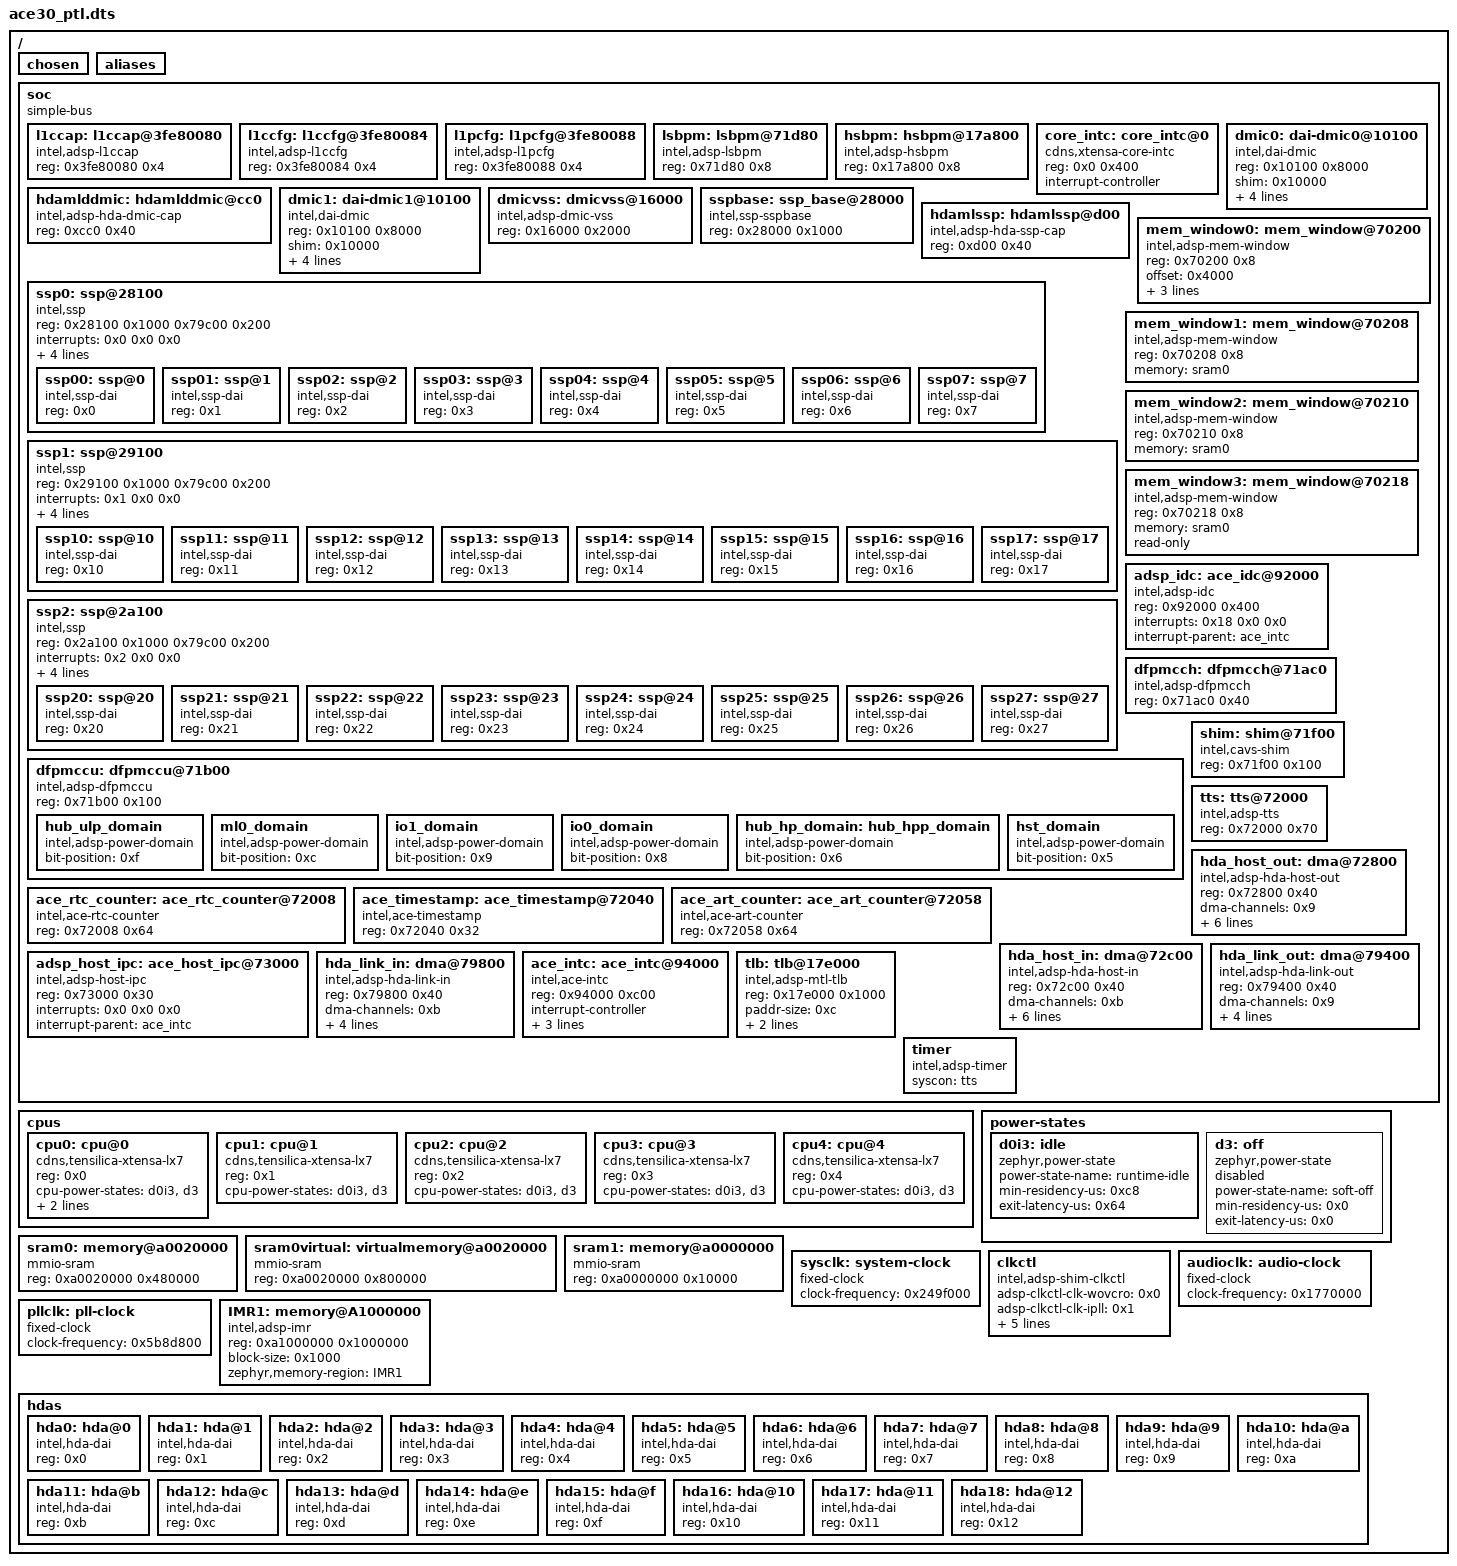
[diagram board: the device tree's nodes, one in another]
/dts-v1/;

/ {
	#address-cells = < 0x1 >;
	#size-cells = < 0x1 >;
	chosen {
	};
	aliases {
	};
	soc {
		#address-cells = < 0x1 >;
		#size-cells = < 0x1 >;
		compatible = "simple-bus";
		ranges;
		l1ccap: l1ccap@3fe80080 {
			compatible = "intel,adsp-l1ccap";
			reg = < 0x3fe80080 0x4 >;
		};
		l1ccfg: l1ccfg@3fe80084 {
			compatible = "intel,adsp-l1ccfg";
			reg = < 0x3fe80084 0x4 >;
		};
		l1pcfg: l1pcfg@3fe80088 {
			compatible = "intel,adsp-l1pcfg";
			reg = < 0x3fe80088 0x4 >;
		};
		lsbpm: lsbpm@71d80 {
			compatible = "intel,adsp-lsbpm";
			reg = < 0x71d80 0x8 >;
		};
		hsbpm: hsbpm@17a800 {
			compatible = "intel,adsp-hsbpm";
			reg = < 0x17a800 0x8 >;
		};
		core_intc: core_intc@0 {
			compatible = "cdns,xtensa-core-intc";
			reg = < 0x0 0x400 >;
			interrupt-controller;
			#interrupt-cells = < 0x3 >;
			phandle = < 0x8 >;
		};
		hdamlddmic: hdamlddmic@cc0 {
			compatible = "intel,adsp-hda-dmic-cap";
			reg = < 0xcc0 0x40 >;
			status = "okay";
		};
		dmic0: dai-dmic0@10100 {
			compatible = "intel,dai-dmic";
			reg = < 0x10100 0x8000 >;
			shim = < 0x10000 >;
			fifo = < 0x8 >;
			interrupts = < 0x8 0x0 0x0 >;
			interrupt-parent = < &ace_intc >;
			power-domain = < &hub_ulp_domain >;
		};
		dmic1: dai-dmic1@10100 {
			compatible = "intel,dai-dmic";
			reg = < 0x10100 0x8000 >;
			shim = < 0x10000 >;
			fifo = < 0x108 >;
			interrupts = < 0x8 0x0 0x0 >;
			interrupt-parent = < &ace_intc >;
			power-domain = < &hub_ulp_domain >;
		};
		dmicvss: dmicvss@16000 {
			compatible = "intel,adsp-dmic-vss";
			reg = < 0x16000 0x2000 >;
			status = "okay";
		};
		sspbase: ssp_base@28000 {
			compatible = "intel,ssp-sspbase";
			reg = < 0x28000 0x1000 >;
		};
		hdamlssp: hdamlssp@d00 {
			compatible = "intel,adsp-hda-ssp-cap";
			reg = < 0xd00 0x40 >;
			status = "okay";
		};
		ssp0: ssp@28100 {
			compatible = "intel,ssp";
			#address-cells = < 0x1 >;
			#size-cells = < 0x0 >;
			reg = < 0x28100 0x1000 0x79c00 0x200 >;
			interrupts = < 0x0 0x0 0x0 >;
			interrupt-parent = < &ace_intc >;
			dmas = < &hda_link_out 0x1 &hda_link_in 0x1 >;
			dma-names = "tx", "rx";
			ssp-index = < 0x0 >;
			power-domain = < &io0_domain >;
			status = "okay";
			ssp00: ssp@0 {
				compatible = "intel,ssp-dai";
				reg = < 0x0 >;
				status = "okay";
			};
			ssp01: ssp@1 {
				compatible = "intel,ssp-dai";
				reg = < 0x1 >;
				status = "okay";
			};
			ssp02: ssp@2 {
				compatible = "intel,ssp-dai";
				reg = < 0x2 >;
				status = "okay";
			};
			ssp03: ssp@3 {
				compatible = "intel,ssp-dai";
				reg = < 0x3 >;
				status = "okay";
			};
			ssp04: ssp@4 {
				compatible = "intel,ssp-dai";
				reg = < 0x4 >;
				status = "okay";
			};
			ssp05: ssp@5 {
				compatible = "intel,ssp-dai";
				reg = < 0x5 >;
				status = "okay";
			};
			ssp06: ssp@6 {
				compatible = "intel,ssp-dai";
				reg = < 0x6 >;
				status = "okay";
			};
			ssp07: ssp@7 {
				compatible = "intel,ssp-dai";
				reg = < 0x7 >;
				status = "okay";
			};
		};
		ssp1: ssp@29100 {
			compatible = "intel,ssp";
			#address-cells = < 0x1 >;
			#size-cells = < 0x0 >;
			reg = < 0x29100 0x1000 0x79c00 0x200 >;
			interrupts = < 0x1 0x0 0x0 >;
			interrupt-parent = < &ace_intc >;
			dmas = < &hda_link_out 0x2 &hda_link_in 0x2 >;
			dma-names = "tx", "rx";
			ssp-index = < 0x1 >;
			power-domain = < &io0_domain >;
			status = "okay";
			ssp10: ssp@10 {
				compatible = "intel,ssp-dai";
				reg = < 0x10 >;
				status = "okay";
			};
			ssp11: ssp@11 {
				compatible = "intel,ssp-dai";
				reg = < 0x11 >;
				status = "okay";
			};
			ssp12: ssp@12 {
				compatible = "intel,ssp-dai";
				reg = < 0x12 >;
				status = "okay";
			};
			ssp13: ssp@13 {
				compatible = "intel,ssp-dai";
				reg = < 0x13 >;
				status = "okay";
			};
			ssp14: ssp@14 {
				compatible = "intel,ssp-dai";
				reg = < 0x14 >;
				status = "okay";
			};
			ssp15: ssp@15 {
				compatible = "intel,ssp-dai";
				reg = < 0x15 >;
				status = "okay";
			};
			ssp16: ssp@16 {
				compatible = "intel,ssp-dai";
				reg = < 0x16 >;
				status = "okay";
			};
			ssp17: ssp@17 {
				compatible = "intel,ssp-dai";
				reg = < 0x17 >;
				status = "okay";
			};
		};
		ssp2: ssp@2a100 {
			compatible = "intel,ssp";
			#address-cells = < 0x1 >;
			#size-cells = < 0x0 >;
			reg = < 0x2a100 0x1000 0x79c00 0x200 >;
			interrupts = < 0x2 0x0 0x0 >;
			interrupt-parent = < &ace_intc >;
			dmas = < &hda_link_out 0x3 &hda_link_in 0x3 >;
			dma-names = "tx", "rx";
			ssp-index = < 0x2 >;
			power-domain = < &io0_domain >;
			status = "okay";
			ssp20: ssp@20 {
				compatible = "intel,ssp-dai";
				reg = < 0x20 >;
				status = "okay";
			};
			ssp21: ssp@21 {
				compatible = "intel,ssp-dai";
				reg = < 0x21 >;
				status = "okay";
			};
			ssp22: ssp@22 {
				compatible = "intel,ssp-dai";
				reg = < 0x22 >;
				status = "okay";
			};
			ssp23: ssp@23 {
				compatible = "intel,ssp-dai";
				reg = < 0x23 >;
				status = "okay";
			};
			ssp24: ssp@24 {
				compatible = "intel,ssp-dai";
				reg = < 0x24 >;
				status = "okay";
			};
			ssp25: ssp@25 {
				compatible = "intel,ssp-dai";
				reg = < 0x25 >;
				status = "okay";
			};
			ssp26: ssp@26 {
				compatible = "intel,ssp-dai";
				reg = < 0x26 >;
				status = "okay";
			};
			ssp27: ssp@27 {
				compatible = "intel,ssp-dai";
				reg = < 0x27 >;
				status = "okay";
			};
		};
		mem_window0: mem_window@70200 {
			compatible = "intel,adsp-mem-window";
			reg = < 0x70200 0x8 >;
			offset = < 0x4000 >;
			memory = < &sram0 >;
			initialize;
			read-only;
		};
		mem_window1: mem_window@70208 {
			compatible = "intel,adsp-mem-window";
			reg = < 0x70208 0x8 >;
			memory = < &sram0 >;
		};
		mem_window2: mem_window@70210 {
			compatible = "intel,adsp-mem-window";
			reg = < 0x70210 0x8 >;
			memory = < &sram0 >;
		};
		mem_window3: mem_window@70218 {
			compatible = "intel,adsp-mem-window";
			reg = < 0x70218 0x8 >;
			memory = < &sram0 >;
			read-only;
		};
		adsp_idc: ace_idc@92000 {
			compatible = "intel,adsp-idc";
			reg = < 0x92000 0x400 >;
			interrupts = < 0x18 0x0 0x0 >;
			interrupt-parent = < &ace_intc >;
		};
		dfpmcch: dfpmcch@71ac0 {
			compatible = "intel,adsp-dfpmcch";
			reg = < 0x71ac0 0x40 >;
		};
		dfpmccu: dfpmccu@71b00 {
			compatible = "intel,adsp-dfpmccu";
			reg = < 0x71b00 0x100 >;
			hub_ulp_domain: hub_ulp_domain {
				compatible = "intel,adsp-power-domain";
				bit-position = < 0xf >;
				phandle = < 0x2 >;
			};
			ml0_domain: ml0_domain {
				compatible = "intel,adsp-power-domain";
				bit-position = < 0xc >;
			};
			io1_domain: io1_domain {
				compatible = "intel,adsp-power-domain";
				bit-position = < 0x9 >;
			};
			io0_domain: io0_domain {
				compatible = "intel,adsp-power-domain";
				bit-position = < 0x8 >;
				phandle = < 0x5 >;
			};
			hub_hp_domain: hub_hpp_domain {
				compatible = "intel,adsp-power-domain";
				bit-position = < 0x6 >;
			};
			hst_domain: hst_domain {
				compatible = "intel,adsp-power-domain";
				bit-position = < 0x5 >;
				phandle = < 0x7 >;
			};
		};
		shim: shim@71f00 {
			compatible = "intel,cavs-shim";
			reg = < 0x71f00 0x100 >;
		};
		tts: tts@72000 {
			compatible = "intel,adsp-tts";
			reg = < 0x72000 0x70 >;
			status = "okay";
			phandle = < 0x9 >;
		};
		ace_rtc_counter: ace_rtc_counter@72008 {
			compatible = "intel,ace-rtc-counter";
			reg = < 0x72008 0x64 >;
		};
		ace_timestamp: ace_timestamp@72040 {
			compatible = "intel,ace-timestamp";
			reg = < 0x72040 0x32 >;
		};
		ace_art_counter: ace_art_counter@72058 {
			compatible = "intel,ace-art-counter";
			reg = < 0x72058 0x64 >;
		};
		hda_host_out: dma@72800 {
			compatible = "intel,adsp-hda-host-out";
			#dma-cells = < 0x1 >;
			reg = < 0x72800 0x40 >;
			dma-channels = < 0x9 >;
			dma-buf-addr-alignment = < 0x80 >;
			dma-buf-size-alignment = < 0x20 >;
			dma-copy-alignment = < 0x20 >;
			power-domain = < &hst_domain >;
			interrupts = < 0xd 0x0 0x0 >;
			interrupt-parent = < &ace_intc >;
			status = "okay";
		};
		hda_host_in: dma@72c00 {
			compatible = "intel,adsp-hda-host-in";
			#dma-cells = < 0x1 >;
			reg = < 0x72c00 0x40 >;
			dma-channels = < 0xb >;
			dma-buf-addr-alignment = < 0x80 >;
			dma-buf-size-alignment = < 0x20 >;
			dma-copy-alignment = < 0x20 >;
			power-domain = < &hst_domain >;
			interrupts = < 0xc 0x0 0x0 >;
			interrupt-parent = < &ace_intc >;
			status = "okay";
		};
		adsp_host_ipc: ace_host_ipc@73000 {
			compatible = "intel,adsp-host-ipc";
			status = "okay";
			reg = < 0x73000 0x30 >;
			interrupts = < 0x0 0x0 0x0 >;
			interrupt-parent = < &ace_intc >;
		};
		hda_link_out: dma@79400 {
			compatible = "intel,adsp-hda-link-out";
			#dma-cells = < 0x1 >;
			reg = < 0x79400 0x40 >;
			dma-channels = < 0x9 >;
			dma-buf-addr-alignment = < 0x80 >;
			dma-buf-size-alignment = < 0x20 >;
			dma-copy-alignment = < 0x20 >;
			power-domain = < &io0_domain >;
			status = "okay";
			phandle = < 0x3 >;
		};
		hda_link_in: dma@79800 {
			compatible = "intel,adsp-hda-link-in";
			#dma-cells = < 0x1 >;
			reg = < 0x79800 0x40 >;
			dma-channels = < 0xb >;
			dma-buf-addr-alignment = < 0x80 >;
			dma-buf-size-alignment = < 0x20 >;
			dma-copy-alignment = < 0x20 >;
			power-domain = < &io0_domain >;
			status = "okay";
			phandle = < 0x4 >;
		};
		ace_intc: ace_intc@94000 {
			compatible = "intel,ace-intc";
			reg = < 0x94000 0xc00 >;
			interrupt-controller;
			#interrupt-cells = < 0x3 >;
			interrupts = < 0x4 0x0 0x0 >;
			num-irqs = < 0x1c >;
			interrupt-parent = < &core_intc >;
			phandle = < 0x1 >;
		};
		tlb: tlb@17e000 {
			compatible = "intel,adsp-mtl-tlb";
			reg = < 0x17e000 0x1000 >;
			paddr-size = < 0xc >;
			exec-bit-idx = < 0xe >;
			write-bit-idx = < 0xf >;
		};
		timer: timer {
			compatible = "intel,adsp-timer";
			syscon = < &tts >;
		};
	};
	cpus {
		#address-cells = < 0x1 >;
		#size-cells = < 0x0 >;
		cpu0: cpu@0 {
			device_type = "cpu";
			compatible = "cdns,tensilica-xtensa-lx7";
			reg = < 0x0 >;
			cpu-power-states = < &d0i3 &d3 >;
			i-cache-line-size = < 0x40 >;
			d-cache-line-size = < 0x40 >;
		};
		cpu1: cpu@1 {
			device_type = "cpu";
			compatible = "cdns,tensilica-xtensa-lx7";
			reg = < 0x1 >;
			cpu-power-states = < &d0i3 &d3 >;
		};
		cpu2: cpu@2 {
			device_type = "cpu";
			compatible = "cdns,tensilica-xtensa-lx7";
			reg = < 0x2 >;
			cpu-power-states = < &d0i3 &d3 >;
		};
		cpu3: cpu@3 {
			device_type = "cpu";
			compatible = "cdns,tensilica-xtensa-lx7";
			reg = < 0x3 >;
			cpu-power-states = < &d0i3 &d3 >;
		};
		cpu4: cpu@4 {
			device_type = "cpu";
			compatible = "cdns,tensilica-xtensa-lx7";
			reg = < 0x4 >;
			cpu-power-states = < &d0i3 &d3 >;
		};
	};
	power-states {
		d0i3: idle {
			compatible = "zephyr,power-state";
			power-state-name = "runtime-idle";
			min-residency-us = < 0xc8 >;
			exit-latency-us = < 0x64 >;
			phandle = < 0xa >;
		};
		d3: off {
			compatible = "zephyr,power-state";
			power-state-name = "soft-off";
			min-residency-us = < 0x0 >;
			exit-latency-us = < 0x0 >;
			status = "disabled";
			phandle = < 0xb >;
		};
	};
	sram0: memory@a0020000 {
		device_type = "memory";
		compatible = "mmio-sram";
		reg = < 0xa0020000 0x480000 >;
		phandle = < 0x6 >;
	};
	sram0virtual: virtualmemory@a0020000 {
		device_type = "memory";
		compatible = "mmio-sram";
		reg = < 0xa0020000 0x800000 >;
	};
	sram1: memory@a0000000 {
		device_type = "memory";
		compatible = "mmio-sram";
		reg = < 0xa0000000 0x10000 >;
	};
	sysclk: system-clock {
		compatible = "fixed-clock";
		clock-frequency = < 0x249f000 >;
		#clock-cells = < 0x0 >;
	};
	clkctl: clkctl {
		compatible = "intel,adsp-shim-clkctl";
		adsp-clkctl-clk-wovcro = < 0x0 >;
		adsp-clkctl-clk-ipll = < 0x1 >;
		adsp-clkctl-freq-enc = < 0xc 0x4 >;
		adsp-clkctl-freq-mask = < 0x0 0x0 >;
		adsp-clkctl-freq-default = < 0x1 >;
		adsp-clkctl-freq-lowest = < 0x0 >;
		wovcro-supported;
	};
	audioclk: audio-clock {
		compatible = "fixed-clock";
		clock-frequency = < 0x1770000 >;
		#clock-cells = < 0x0 >;
	};
	pllclk: pll-clock {
		compatible = "fixed-clock";
		clock-frequency = < 0x5b8d800 >;
		#clock-cells = < 0x0 >;
	};
	IMR1: memory@A1000000 {
		compatible = "intel,adsp-imr";
		reg = < 0xa1000000 0x1000000 >;
		block-size = < 0x1000 >;
		zephyr,memory-region = "IMR1";
	};
	hdas {
		#address-cells = < 0x1 >;
		#size-cells = < 0x0 >;
		hda0: hda@0 {
			compatible = "intel,hda-dai";
			status = "okay";
			reg = < 0x0 >;
		};
		hda1: hda@1 {
			compatible = "intel,hda-dai";
			status = "okay";
			reg = < 0x1 >;
		};
		hda2: hda@2 {
			compatible = "intel,hda-dai";
			status = "okay";
			reg = < 0x2 >;
		};
		hda3: hda@3 {
			compatible = "intel,hda-dai";
			status = "okay";
			reg = < 0x3 >;
		};
		hda4: hda@4 {
			compatible = "intel,hda-dai";
			status = "okay";
			reg = < 0x4 >;
		};
		hda5: hda@5 {
			compatible = "intel,hda-dai";
			status = "okay";
			reg = < 0x5 >;
		};
		hda6: hda@6 {
			compatible = "intel,hda-dai";
			status = "okay";
			reg = < 0x6 >;
		};
		hda7: hda@7 {
			compatible = "intel,hda-dai";
			status = "okay";
			reg = < 0x7 >;
		};
		hda8: hda@8 {
			compatible = "intel,hda-dai";
			status = "okay";
			reg = < 0x8 >;
		};
		hda9: hda@9 {
			compatible = "intel,hda-dai";
			status = "okay";
			reg = < 0x9 >;
		};
		hda10: hda@a {
			compatible = "intel,hda-dai";
			status = "okay";
			reg = < 0xa >;
		};
		hda11: hda@b {
			compatible = "intel,hda-dai";
			status = "okay";
			reg = < 0xb >;
		};
		hda12: hda@c {
			compatible = "intel,hda-dai";
			status = "okay";
			reg = < 0xc >;
		};
		hda13: hda@d {
			compatible = "intel,hda-dai";
			status = "okay";
			reg = < 0xd >;
		};
		hda14: hda@e {
			compatible = "intel,hda-dai";
			status = "okay";
			reg = < 0xe >;
		};
		hda15: hda@f {
			compatible = "intel,hda-dai";
			status = "okay";
			reg = < 0xf >;
		};
		hda16: hda@10 {
			compatible = "intel,hda-dai";
			status = "okay";
			reg = < 0x10 >;
		};
		hda17: hda@11 {
			compatible = "intel,hda-dai";
			status = "okay";
			reg = < 0x11 >;
		};
		hda18: hda@12 {
			compatible = "intel,hda-dai";
			status = "okay";
			reg = < 0x12 >;
		};
	};
};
